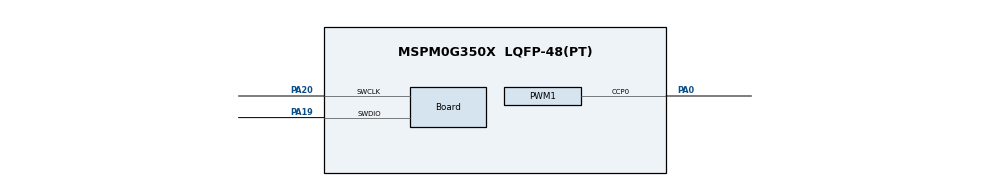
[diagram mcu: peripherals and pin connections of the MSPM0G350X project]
/**
 * @cliArgs --device "MSPM0G350X" --part "Default" --package "LQFP-48(PT)" --product "mspm0_sdk@2.09.00.00"
 * @versions {"tool":"1.26.2+4477"}
 */
scripting.excludeFromBuild("device_linker.cmd");
scripting.excludeFromBuild("device_linker.lds");
scripting.excludeFromBuild("device.opt");
scripting.excludeFromBuild("device.cmd.genlibs");
scripting.excludeFromBuild("device.lds.genlibs");
scripting.excludeFromBuild("Event.dot");

/**
 * Import the modules used in this configuration.
 */
const CAPTURE  = scripting.addModule("/ti/driverlib/CAPTURE", {}, false);
const CAPTURE1 = CAPTURE.addInstance();
const PWM      = scripting.addModule("/ti/driverlib/PWM", {}, false);
const PWM1     = PWM.addInstance();
const SYSCTL   = scripting.addModule("/ti/driverlib/SYSCTL");

/**
 * Write custom configuration values to the imported modules.
 */
CAPTURE1.$name                       = "CAPTURE_0";
CAPTURE1.event1ControllerInterruptEn = ["ZERO_EVENT"];
CAPTURE1.subscriberPort              = "FSUB0";
CAPTURE1.subscriberChannel           = 1;
CAPTURE1.interruptPriority           = "0";
CAPTURE1.captSelect                  = "Trigger";
CAPTURE1.interrupts                  = ["CC0_DN","CC0_UP"];
CAPTURE1.captEdgeDetection           = "EDGE";
CAPTURE1.peripheral.$assign          = "TIMG0";

const Board                       = scripting.addModule("/ti/driverlib/Board", {}, false);
Board.peripheral.$assign          = "DEBUGSS";
Board.peripheral.swclkPin.$assign = "PA20";
Board.peripheral.swdioPin.$assign = "PA19";

PWM1.$name                       = "PWM_0";
PWM1.ccIndex                     = [0];
PWM1.clockDivider                = 8;
PWM1.clockPrescale               = 2;
PWM1.event1PublisherChannel      = 1;
PWM1.subscriberChannel           = 2;
PWM1.timerCount                  = 200;
PWM1.pwmMode                     = "CENTER_ALIGN";
PWM1.event1ControllerInterruptEn = ["CC0_DN_EVENT"];
PWM1.PWM_CHANNEL_0.$name         = "ti_driverlib_pwm_PWMTimerCC0";
PWM1.PWM_CHANNEL_0.dutyCycle     = 50;
PWM1.ccp0PinConfig.$name         = "ti_driverlib_gpio_GPIOPinGeneric0";
PWM1.peripheral.$assign          = "TIMA0";
PWM1.peripheral.ccp0Pin.$assign  = "PA0";

SYSCTL.forceDefaultClkConfig = true;
SYSCTL.peripheral.$assign    = "SYSCTL";

const ProjectConfig              = scripting.addModule("/ti/project_config/ProjectConfig", {}, false);
ProjectConfig.migrationCondition = true;
